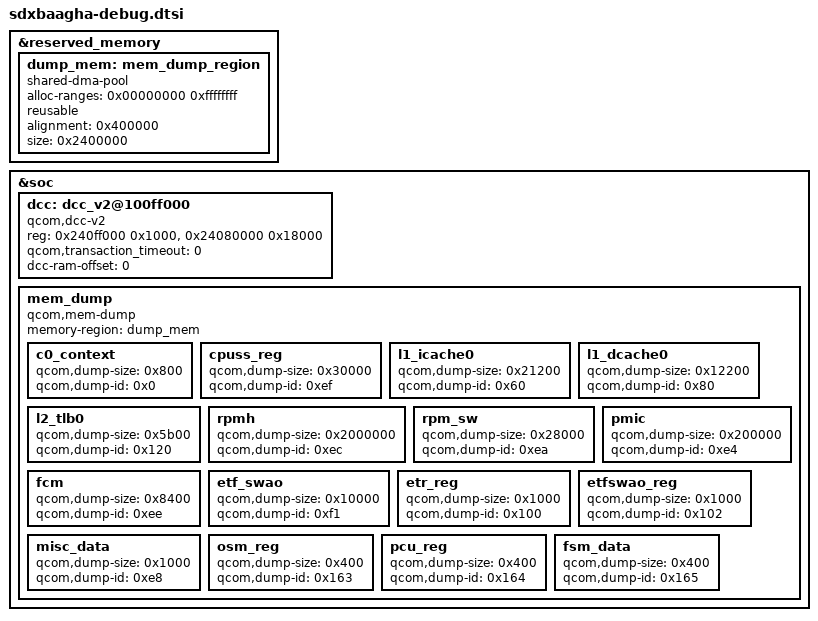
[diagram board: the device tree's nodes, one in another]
#include <dt-bindings/soc/qcom,dcc_v2.h>

&reserved_memory {
	#address-cells = <1>;
	#size-cells = <1>;
	ranges;

	dump_mem: mem_dump_region {
		compatible = "shared-dma-pool";
		alloc-ranges = <0x00000000 0xffffffff>;
		reusable;
		alignment = <0x400000>;
		size = <0x2400000>;
	};
};

&soc {
	dcc: dcc_v2@100ff000 {
		compatible = "qcom,dcc-v2";
		reg = <0x240ff000 0x1000>,
		      <0x24080000 0x18000>;

		qcom,transaction_timeout = <0>;
		reg-names = "dcc-base", "dcc-ram-base";
		dcc-ram-offset = <0>;
	};

	mem_dump {
		compatible = "qcom,mem-dump";
		memory-region = <&dump_mem>;

		c0_context {
			qcom,dump-size = <0x800>;
			qcom,dump-id = <0x0>;
		};

		cpuss_reg {
			qcom,dump-size = <0x30000>;
			qcom,dump-id = <0xef>;
		};

		l1_icache0 {
			qcom,dump-size = <0x21200>;
			qcom,dump-id = <0x60>;
		};

		l1_dcache0 {
			qcom,dump-size = <0x12200>;
			qcom,dump-id = <0x80>;
		};

		l2_tlb0 {
			qcom,dump-size = <0x5b00>;
			qcom,dump-id = <0x120>;
		};

		rpmh {
			qcom,dump-size = <0x2000000>;
			qcom,dump-id = <0xec>;
		};

		rpm_sw {
			qcom,dump-size = <0x28000>;
			qcom,dump-id = <0xea>;
		};

		pmic {
			qcom,dump-size = <0x200000>;
			qcom,dump-id = <0xe4>;
		};

		fcm {
			qcom,dump-size = <0x8400>;
			qcom,dump-id = <0xee>;
		};

		etf_swao {
			qcom,dump-size = <0x10000>;
			qcom,dump-id = <0xf1>;
		};

		etr_reg {
			qcom,dump-size = <0x1000>;
			qcom,dump-id = <0x100>;
		};

		etfswao_reg {
			qcom,dump-size = <0x1000>;
			qcom,dump-id = <0x102>;
		};

		misc_data {
			qcom,dump-size = <0x1000>;
			qcom,dump-id = <0xe8>;
		};

		osm_reg {
			qcom,dump-size = <0x400>;
			qcom,dump-id = <0x163>;
		};

		pcu_reg {
			qcom,dump-size = <0x400>;
			qcom,dump-id = <0x164>;
		};

		fsm_data {
			qcom,dump-size = <0x400>;
			qcom,dump-id = <0x165>;
		};
	};
};
